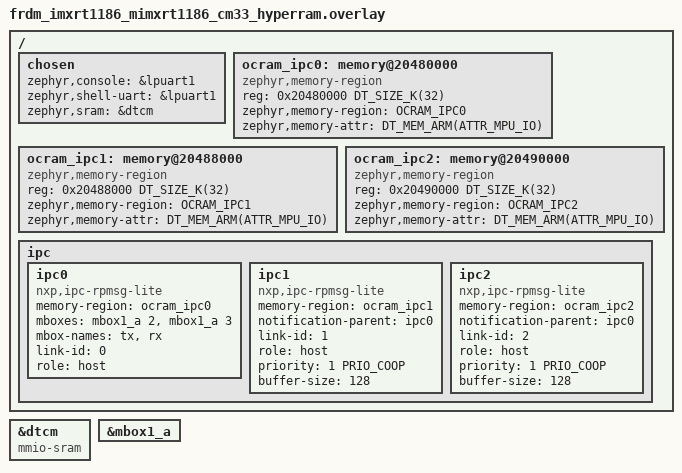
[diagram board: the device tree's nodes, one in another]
/*
 * Copyright 2026 NXP
 *
 * SPDX-License-Identifier: Apache-2.0
 */

#include <zephyr/dt-bindings/ipc_service/static_vrings.h>
#include <zephyr/dt-bindings/memory-attr/memory-attr-arm.h>

/ {
	chosen {
		zephyr,console = &lpuart1;
		zephyr,shell-uart = &lpuart1;
		/*
		 * Move CM33 SRAM to DTCM so HyperRAM is free
		 * for CM7 code execution.
		 */
		zephyr,sram = &dtcm;
	};

	ocram_ipc0: memory@20480000 {
		compatible = "zephyr,memory-region", "mmio-sram";
		reg = <0x20480000 DT_SIZE_K(32)>;
		zephyr,memory-region = "OCRAM_IPC0";
		zephyr,memory-attr = <DT_MEM_ARM(ATTR_MPU_IO)>;
	};

	ocram_ipc1: memory@20488000 {
		compatible = "zephyr,memory-region", "mmio-sram";
		reg = <0x20488000 DT_SIZE_K(32)>;
		zephyr,memory-region = "OCRAM_IPC1";
		zephyr,memory-attr = <DT_MEM_ARM(ATTR_MPU_IO)>;
	};

	ocram_ipc2: memory@20490000 {
		compatible = "zephyr,memory-region", "mmio-sram";
		reg = <0x20490000 DT_SIZE_K(32)>;
		zephyr,memory-region = "OCRAM_IPC2";
		zephyr,memory-attr = <DT_MEM_ARM(ATTR_MPU_IO)>;
	};

	ipc {
		/delete-node/ ipc0;

		ipc0: ipc0 {
			compatible = "nxp,ipc-rpmsg-lite";
			memory-region = <&ocram_ipc0>;
			mboxes = <&mbox1_a 2>, <&mbox1_a 3>;
			mbox-names = "tx", "rx";
			link-id = <0>;
			role = "host";
			status = "okay";
		};

		ipc1: ipc1 {
			compatible = "nxp,ipc-rpmsg-lite";
			memory-region = <&ocram_ipc1>;
			notification-parent = <&ipc0>;
			link-id = <1>;
			role = "host";
			priority = <1 PRIO_COOP>;
			buffer-size = <128>;
			status = "okay";
		};

		ipc2: ipc2 {
			compatible = "nxp,ipc-rpmsg-lite";
			memory-region = <&ocram_ipc2>;
			notification-parent = <&ipc0>;
			link-id = <2>;
			role = "host";
			priority = <1 PRIO_COOP>;
			buffer-size = <128>;
			status = "okay";
		};
	};
};

&dtcm {
	/*
	 * Remove zephyr,memory-region binding so the linker does not
	 * place a dedicated DTCM section. Change compatible to plain
	 * mmio-sram so the required 'zephyr,memory-region' property
	 * from the zephyr,memory-region binding is no longer enforced.
	 */
	compatible = "mmio-sram";
};

&mbox1_a {
	status = "okay";
};
